AUTOSAR XML (schema 00048)
package /SoftwareTypes/ComponentTypes
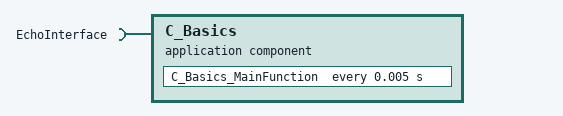
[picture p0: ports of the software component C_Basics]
  application sw component type C_Basics
    require port EchoInterface: nonqueued-receiver-com-spec{data-element=Echo, max-delta-counter-init=-1, filter=data-filter-type=ALWAYS, init-value=fields=0}, required-interface=EchoInterface
    behavior C_Basics_ib: data-type-mapping=Data_Type_Mappings
      timing event TMT_C_Basics_MainFunction: start-on-event=C_Basics_MainFunction, period=0.005
      runnable C_Basics_MainFunction
        data-receive-point-by-arguments:
          access REC_EchoInterface_Echo: accessed-variable=EchoInterface.Echo
